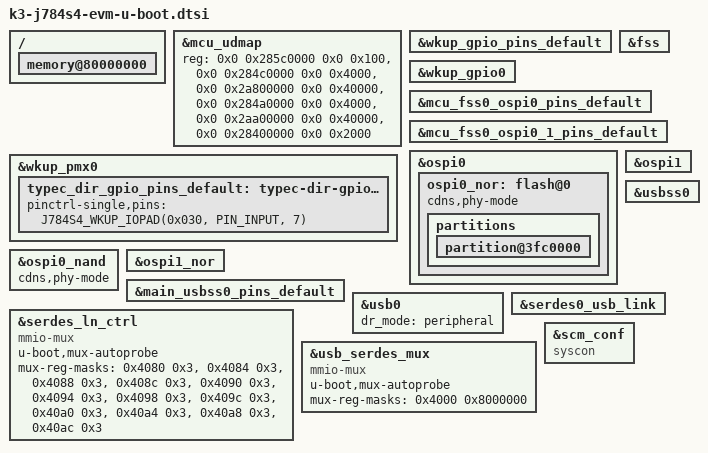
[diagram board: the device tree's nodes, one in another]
// SPDX-License-Identifier: GPL-2.0-only
/*
 * Copyright (C) 2023 Texas Instruments Incorporated - https://www.ti.com/
 */

#include "k3-j784s4-binman.dtsi"

/ {
	memory@80000000 {
		bootph-all;
	};
};

&mcu_udmap {
	reg =   <0x0 0x285c0000 0x0 0x100>,
		<0x0 0x284c0000 0x0 0x4000>,
		<0x0 0x2a800000 0x0 0x40000>,
		<0x0 0x284a0000 0x0 0x4000>,
		<0x0 0x2aa00000 0x0 0x40000>,
		<0x0 0x28400000 0x0 0x2000>;
	reg-names = "gcfg", "rchan", "rchanrt", "tchan",
		    "tchanrt", "rflow";
	bootph-pre-ram;
};

&wkup_gpio_pins_default {
	bootph-pre-ram;
};

&wkup_gpio0 {
	bootph-pre-ram;
};

&wkup_pmx0 {
	bootph-pre-ram;

	typec_dir_gpio_pins_default: typec-dir-gpio-pins-default {
		pinctrl-single,pins = <
			/* (A33) MCU_OSPI0_CSn1.WKUP_GPIO0_28 */
			J784S4_WKUP_IOPAD(0x030, PIN_INPUT, 7)
		>;
	};
};

&fss {
	bootph-pre-ram;
};

&mcu_fss0_ospi0_pins_default {
	bootph-pre-ram;
};

&mcu_fss0_ospi0_1_pins_default {
	bootph-pre-ram;
};

&ospi0 {
	bootph-pre-ram;

	ospi0_nor: flash@0 {
		cdns,phy-mode;
		bootph-pre-ram;

		partitions {
			bootph-pre-ram;

			partition@3fc0000 {
				bootph-pre-ram;
			};
		};
	};
};

&ospi0_nand {
	bootph-pre-ram;
	cdns,phy-mode;
};

&ospi1 {
	bootph-pre-ram;
};

&ospi1_nor {
	bootph-pre-ram;
};

&main_usbss0_pins_default {
	bootph-pre-ram;
};

&usbss0 {
	bootph-pre-ram;
};

&usb0 {
	dr_mode = "peripheral";
	bootph-pre-ram;
};

&serdes0_usb_link {
	bootph-pre-ram;
};

&serdes_ln_ctrl {
	u-boot,mux-autoprobe;
	compatible = "mmio-mux";
	mux-reg-masks = <0x4080 0x3>, <0x4084 0x3>, /* SERDES0 lane0/1 select */
			<0x4088 0x3>, <0x408c 0x3>, /* SERDES0 lane2/3 select */
			<0x4090 0x3>, <0x4094 0x3>, /* SERDES1 lane0/1 select */
			<0x4098 0x3>, <0x409c 0x3>, /* SERDES1 lane2/3 select */
			<0x40a0 0x3>, <0x40a4 0x3>, /* SERDES2 lane0/1 select */
			<0x40a8 0x3>, <0x40ac 0x3>; /* SERDES2 lane2/3 select */
};

&usb_serdes_mux {
	u-boot,mux-autoprobe;
	compatible = "mmio-mux";
	mux-reg-masks = <0x4000 0x8000000>; /* USB0 to SERDES0 lane 1/3 mux */
};

&scm_conf {
	compatible = "syscon", "simple-mfd";
};
